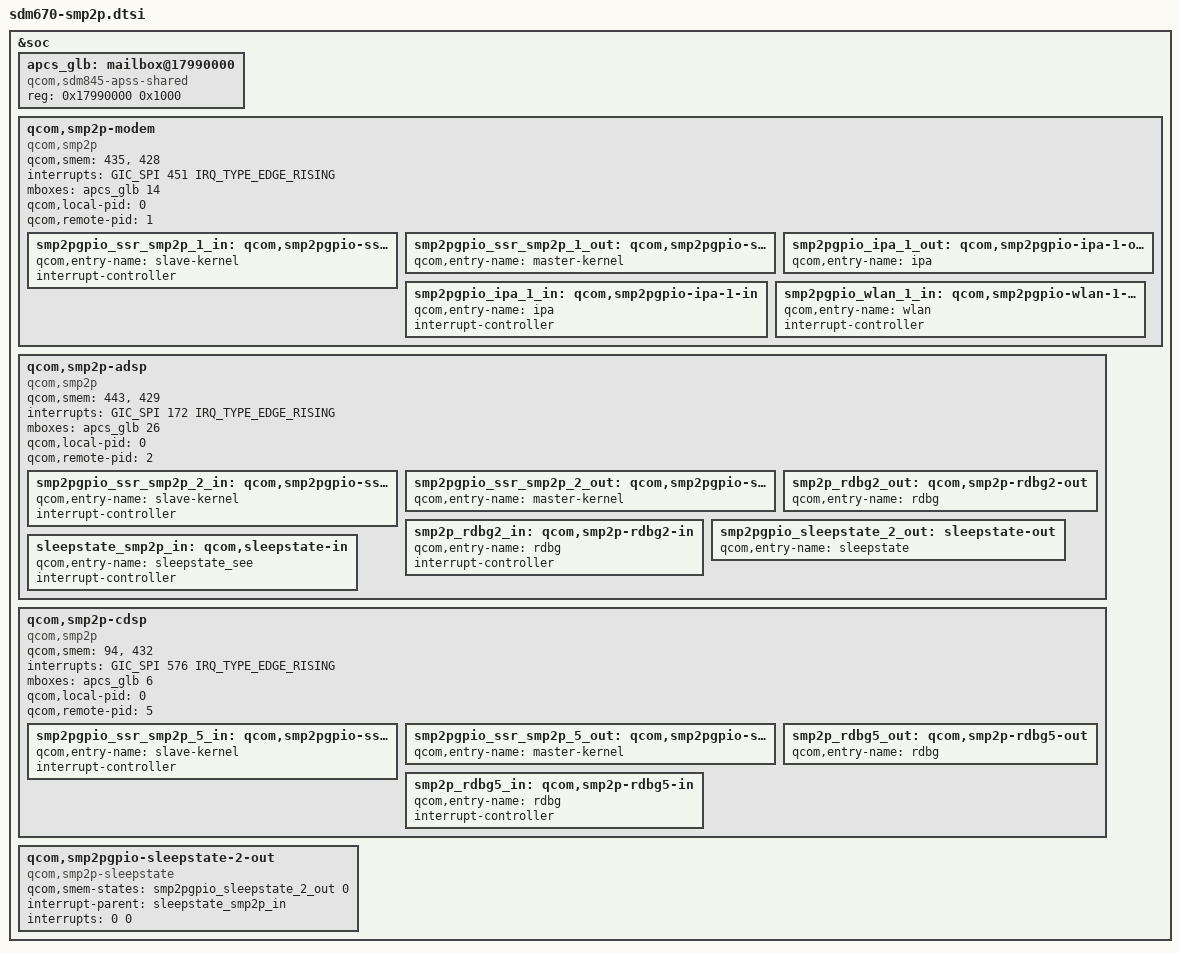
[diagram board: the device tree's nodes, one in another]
/* Copyright (c) 2017-2018, The Linux Foundation. All rights reserved.
 *
 * This program is free software; you can redistribute it and/or modify
 * it under the terms of the GNU General Public License version 2 and
 * only version 2 as published by the Free Software Foundation.
 *
 * This program is distributed in the hope that it will be useful,
 * but WITHOUT ANY WARRANTY; without even the implied warranty of
 * MERCHANTABILITY or FITNESS FOR A PARTICULAR PURPOSE.  See the
 * GNU General Public License for more details.
 */

#include <dt-bindings/interrupt-controller/arm-gic.h>

&soc {
	/* APCS IPC mailbox used by smp2p to kick the remote processors */
	apcs_glb: mailbox@17990000 {
		compatible = "qcom,sdm845-apss-shared";
		reg = <0x17990000 0x1000>;
		#mbox-cells = <1>;
	};

	qcom,smp2p-modem {
		compatible = "qcom,smp2p";
		qcom,smem = <435>, <428>;
		interrupts = <GIC_SPI 451 IRQ_TYPE_EDGE_RISING>;
		mboxes = <&apcs_glb 14>;
		qcom,local-pid = <0>;
		qcom,remote-pid = <1>;

		/* ssr - inbound entry from mss */
		smp2pgpio_ssr_smp2p_1_in: qcom,smp2pgpio-ssr-smp2p-1-in {
			qcom,entry-name = "slave-kernel";
			interrupt-controller;
			#interrupt-cells = <2>;
		};

		/* ssr - outbound entry to mss */
		smp2pgpio_ssr_smp2p_1_out: qcom,smp2pgpio-ssr-smp2p-1-out {
			qcom,entry-name = "master-kernel";
			#qcom,smem-state-cells = <1>;
		};

		/* ipa - outbound entry to mss */
		smp2pgpio_ipa_1_out: qcom,smp2pgpio-ipa-1-out {
			qcom,entry-name = "ipa";
			#qcom,smem-state-cells = <1>;
		};

		/* ipa - inbound entry from mss */
		smp2pgpio_ipa_1_in: qcom,smp2pgpio-ipa-1-in {
			qcom,entry-name = "ipa";
			interrupt-controller;
			#interrupt-cells = <2>;
		};

		/* wlan - inbound entry from mss/WLAN PD */
		smp2pgpio_wlan_1_in: qcom,smp2pgpio-wlan-1-in {
			qcom,entry-name = "wlan";
			interrupt-controller;
			#interrupt-cells = <2>;
		};
	};

	qcom,smp2p-adsp {
		compatible = "qcom,smp2p";
		qcom,smem = <443>, <429>;
		interrupts = <GIC_SPI 172 IRQ_TYPE_EDGE_RISING>;
		mboxes = <&apcs_glb 26>;
		qcom,local-pid = <0>;
		qcom,remote-pid = <2>;

		/* ssr - inbound entry from lpass */
		smp2pgpio_ssr_smp2p_2_in: qcom,smp2pgpio-ssr-smp2p-2-in {
			qcom,entry-name = "slave-kernel";
			interrupt-controller;
			#interrupt-cells = <2>;
		};

		/* ssr - outbound entry to lpass */
		smp2pgpio_ssr_smp2p_2_out: qcom,smp2pgpio-ssr-smp2p-2-out {
			qcom,entry-name = "master-kernel";
			#qcom,smem-state-cells = <1>;
		};

		smp2p_rdbg2_out: qcom,smp2p-rdbg2-out {
			qcom,entry-name = "rdbg";
			#qcom,smem-state-cells = <1>;
		};

		smp2p_rdbg2_in: qcom,smp2p-rdbg2-in {
			qcom,entry-name = "rdbg";
			interrupt-controller;
			#interrupt-cells = <2>;
		};

		smp2pgpio_sleepstate_2_out: sleepstate-out {
			qcom,entry-name = "sleepstate";
			#qcom,smem-state-cells = <1>;
		};

		sleepstate_smp2p_in: qcom,sleepstate-in {
			qcom,entry-name = "sleepstate_see";
			interrupt-controller;
			#interrupt-cells = <2>;
		};
	};

	qcom,smp2p-cdsp {
		compatible = "qcom,smp2p";
		qcom,smem = <94>, <432>;
		interrupts = <GIC_SPI 576 IRQ_TYPE_EDGE_RISING>;
		mboxes = <&apcs_glb 6>;
		qcom,local-pid = <0>;
		qcom,remote-pid = <5>;

		/* ssr - inbound entry from cdsp */
		smp2pgpio_ssr_smp2p_5_in: qcom,smp2pgpio-ssr-smp2p-5-in {
			qcom,entry-name = "slave-kernel";
			interrupt-controller;
			#interrupt-cells = <2>;
		};

		/* ssr - outbound entry to cdsp */
		smp2pgpio_ssr_smp2p_5_out: qcom,smp2pgpio-ssr-smp2p-5-out {
			qcom,entry-name = "master-kernel";
			#qcom,smem-state-cells = <1>;
		};

		smp2p_rdbg5_out: qcom,smp2p-rdbg5-out {
			qcom,entry-name = "rdbg";
			#qcom,smem-state-cells = <1>;
		};

		smp2p_rdbg5_in: qcom,smp2p-rdbg5-in {
			qcom,entry-name = "rdbg";
			interrupt-controller;
			#interrupt-cells = <2>;
		};
	};

	qcom,smp2pgpio-sleepstate-2-out {
		compatible = "qcom,smp2p-sleepstate";
		qcom,smem-states = <&smp2pgpio_sleepstate_2_out 0>;
		interrupt-parent = <&sleepstate_smp2p_in>;
		interrupts = <0 0>;
		interrupt-names = "smp2p-sleepstate-in";
	};

};
